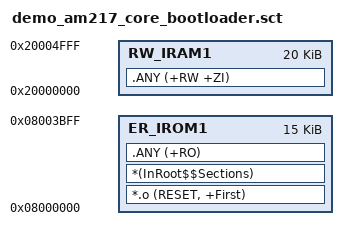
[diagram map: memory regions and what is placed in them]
; *************************************************************
; *** Scatter-Loading Description File generated by uVision ***
; *************************************************************

; ***********************************double*****************************
LR_IROM1 0x08000000 0x00003C00  {    ; load region size_region
  ER_IROM1 0x08000000 0x00003C00  {  ; load address = execution address
   *.o (RESET, +First)
   *(InRoot$$Sections)
   .ANY (+RO)
  }
  RW_IRAM1 0x20000000 0x00005000  {  ; RW data
   .ANY (+RW +ZI)
  }
}

; *********************************single*********************************
;LR_IROM1 0x08000000 0x00007000  {    ; load region size_region
;  ER_IROM1 0x08000000 0x00007000  {  ; load address = execution address
;   *.o (RESET, +First)
;   *(InRoot$$Sections)
;   .ANY (+RO)
;  }
;  RW_IRAM1 0x20000000 0x00005000  {  ; RW data
;   .ANY (+RW +ZI)
;  }
;}

; *****************************************kft*****************************
;LR_IROM1 0x08000000 0x00007000  {    ; load region size_region
;  ER_IROM1 0x08000000 0x00007000  {  ; load address = execution address
;   *.o (RESET, +First)
;   *(InRoot$$Sections)
;   .ANY (+RO)
;  }
;  RW_IRAM1 0x20000000 0x00005000  {  ; RW data
;   .ANY (+RW +ZI)
;  }
;}

